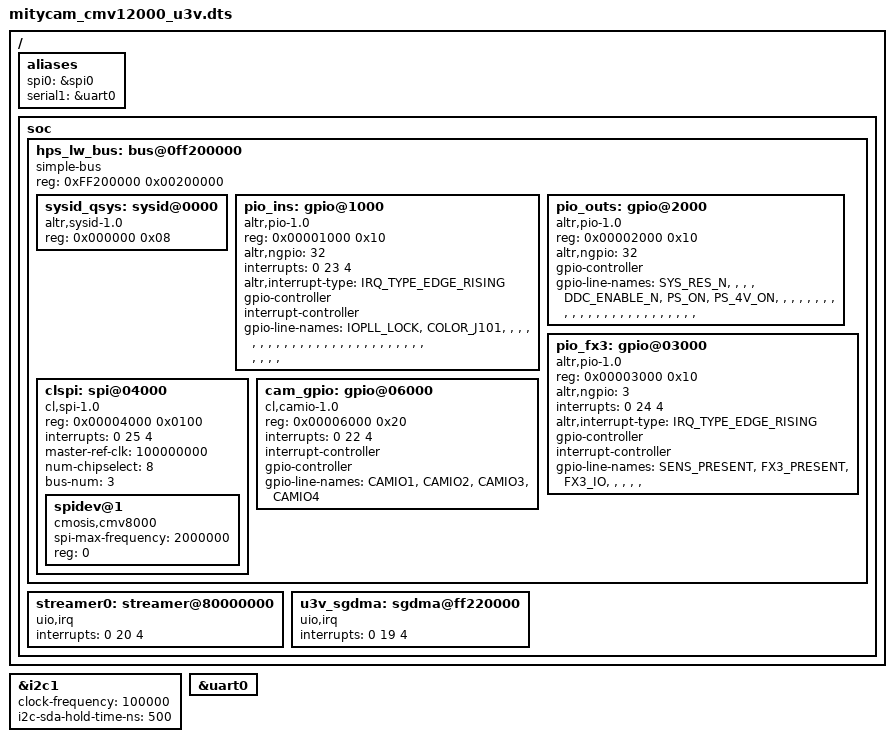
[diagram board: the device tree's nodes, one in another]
/*
 * Copyright (C) 2014-2015 Altera Corporation <www.altera.com>
 *
 * This program is free software; you can redistribute it and/or modify
 * it under the terms of the GNU General Public License as published by
 * the Free Software Foundation; either version 2 of the License, or
 * (at your option) any later version.
 *
 * This program is distributed in the hope that it will be useful,
 * but WITHOUT ANY WARRANTY; without even the implied warranty of
 * MERCHANTABILITY or FITNESS FOR A PARTICULAR PURPOSE.  See the
 * GNU General Public License for more details.
 *
 * You should have received a copy of the GNU General Public License
 * along with this program.  If not, see <http://www.gnu.org/licenses/>.
 */

/dts-v1/;
#include "mitysom_a10s_dsc.dtsi"

/ {
	aliases {
		spi0 = &spi0;
		serial1 = &uart0;
	};

	soc {
		hps_lw_bus: bus@0ff200000 {
			compatible = "simple-bus";
			reg = <0xFF200000 0x00200000>;
			#address-cells = <1>;
			#size-cells = <1>;
			ranges = <0x0 0xFF200000 0x00200000>;
			status = "okay";

			sysid_qsys: sysid@0000 {
				compatible = "altr,sysid-1.0";
				reg = <0x000000 0x08>;
			};

			pio_ins: gpio@1000 {
				compatible = "altr,pio-1.0";
				reg = <0x00001000 0x10>;
				altr,ngpio = <32>;
				interrupts = <0 23 4>;
				altr,interrupt-type = <IRQ_TYPE_EDGE_RISING>;
				#gpio-cells = <2>;
				gpio-controller;
				#interrupt-cells = <1>;
				interrupt-controller;
				gpio-line-names = "IOPLL_LOCK", "COLOR_J101", "", "",
						  "", "", "", "",
						  "", "", "", "",
						  "", "", "", "",
						  "", "", "", "",
						  "", "", "", "",
						  "", "", "", "",
						  "", "", "", "";
			};

			pio_outs: gpio@2000 {
				compatible = "altr,pio-1.0";
				reg = <0x00002000 0x10>;
				altr,ngpio = <32>;
				/* interrupts = <0 23 4>; */
				/* altr,interrupt-type = <IRQ_TYPE_EDGE_RISING>; */
				#gpio-cells = <2>;
				gpio-controller;
				/* #interrupt-cells = <1>; */
				/* interrupt-controller; */
				gpio-line-names = "SYS_RES_N", "", "", "",
						  "DDC_ENABLE_N", "PS_ON", "PS_4V_ON", "",
						  "", "", "", "",
						  "", "", "", "",
						  "", "", "", "",
						  "", "", "", "",
						  "", "", "", "",
						  "", "", "", "";
			};

			pio_fx3: gpio@03000 {
				compatible = "altr,pio-1.0";
				reg = <0x00003000 0x10>;
				altr,ngpio = <3>;
				interrupts = <0 24 4>;
				altr,interrupt-type = <IRQ_TYPE_EDGE_RISING>;
				#gpio-cells = <2>;
				gpio-controller;
				#interrupt-cells = <1>;
				interrupt-controller;
				gpio-line-names = "SENS_PRESENT", "FX3_PRESENT", "FX3_IO", "", "", "", "", "";
			};

			clspi: spi@04000 {
				compatible = "cl,spi-1.0";
				#address-cells = <1>;
				#size-cells = <0>;
				reg = <0x00004000 0x0100>;
				interrupts = <0 25 4>;
				master-ref-clk = <100000000>;
				num-chipselect = <8>;
				bus-num = <3>;

				spidev@1 {
					spi-max-frequency = <2000000>;
					reg = <0>;
					compatible = "cmosis,cmv8000";
				};
			};

			/* mitycam CMV_FRAME_CONTROL      @05000, managed in userspace */

			cam_gpio: gpio@06000 {
				compatible = "cl,camio-1.0";
				reg = <0x00006000 0x20>;
				interrupts = <0 22 4>;
				interrupt-controller;
				#interrupt-cells = <2>;
				gpio-controller;
				#gpio-cells=<2>;
				gpio-line-names = "CAMIO1", "CAMIO2", "CAMIO3", "CAMIO4";
			};

			/* mitycam CMV12000_DATA_PROC     @10000, managed in userspace */
			/* mitycam TEST_PATTERN_GEN       @11000, managed in userspace */
			/* mitycam ROW_ADJUST             @12000, managed in userspace */
			/* mitycam PIXEL_SHIFT            @13000, managed in userspace */
			/* mitycam STREAM_TO_SDRAM_RASTER @18000, managed in userspace */

			/* mitycam U3V SDGMA CSR          @20000, managed in userspace */
			/* mitycam U3V SDGMA DESC         @21000, managed in userspace */
			/* mitycam U3V_FX3                @22000, managed in userspace */

		};

		/* Order of uio is important. Don't reorder, will change /dev/uio# */
		/* Stream to SDRAM Raster */
		streamer0: streamer@80000000 {
			compatible = "uio,irq";
			interrupts = <0 20 4>;
		};

		/* U3V MSGDMA interrupt */
		u3v_sgdma: sgdma@ff220000 {
			compatible = "uio,irq";
			interrupts = <0 19 4>;
		};

		/* Guaissian 5x5 interrupts 
		conv_5x5: canon_5x5@ff20c000 {
			compatible = "uio,irq";
			interrupts = <0 30 4>;
		}; */

		/* bayer demosaic interrupts 
		debayer: debayer@ff212000 {
			compatible = "uio,irq";
			interrupts = <0 28 4>;
		}; */

		/* hdmi reader interrupts 
		hdmi_reader: hdmi_reader@ff239000 {
			compatible = "uio,irq";
			interrupts = <0 22 4>;
		}; */

		/* hdmi CVO interrupts 
		hdmi_cvo: hdmi_cvo@ff23C000 {
			compatible = "uio,irq";
			interrupts = <0 20 4>;
		}; */

		/* hdmi writer interrupts
		hdmi_writer: hdmi_writer@ff381000 {
			compatible = "uio,irq";
			interrupts = <0 21 4>;
		}; */

		/* hdmi switcher interrupts
		hdmi_switcher: hdmi_switcher@ff383000 {
			compatible = "uio,irq";
			interrupts = <0 29 4>;
		}; */
	};
};

&i2c1 {
	status = "okay";
	clock-frequency = <100000>;
        i2c-sda-hold-time-ns = <500>;


	/* USB IO Tri-Color LED */
	/* disabled - used directly by ARM software */
	/* 
	led@62 {
		compatible = "nxp,pca9553";
		reg = <0x62>;
	}; */

	/* Sensor board */

};

/* FX3 comms interface */
&uart0 {
	status = "okay";
};

